# ADuCM410 register map
Vendor: Analog Devices; Series: ADuCM410; File version: 1p0
CPU: CM33 r0p1, little endian, MPU, FPU, 3 interrupt priority bits
Registers are 32-bit, read-write, reset 0x0 unless marked. A register's access mark holds for its fields unless they carry their own. Offsets are from the block's base; [hi:lo] are bit positions; lines under a group give offsets from that group; {n}, {i} and the like mark numbered series; 'fields as' and 'values as' point back to an identical list.

## PLA
Base 0x40006000
{0x0+4i} ELMxcon[{i}] (i=0..31) group — ELMx Configuration Registers
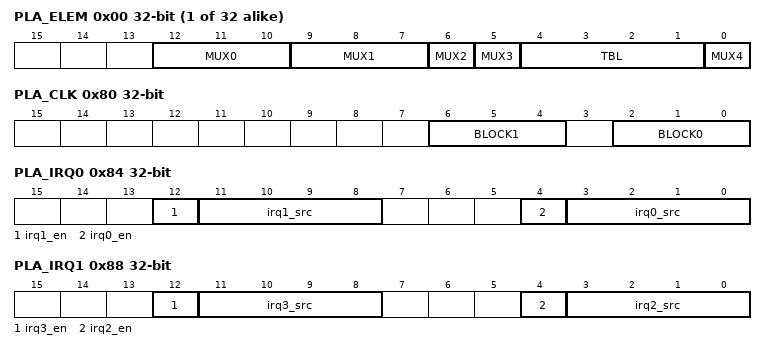
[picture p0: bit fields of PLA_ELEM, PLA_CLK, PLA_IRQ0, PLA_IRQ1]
  0x00 PLA_ELEM — ELEMx Configuration Register
    [12:10] MUX0 — Mux for Even Element Feedback(in Respective Block)
      0=ELEM0 (Feedback from Element 0 (all Except Element 0) / Input from Other Block (Element 0 Only)); 1=ELEM2 (Feedback from Element 2); 2=ELEM4 (Feedback from Element 4); 3=ELEM6 (Feedback from Element 6); 4=ELEM8 (Feedback from Element 8); 5=ELEM10 (Feedback from Element 10); 6=ELEM12 (Feedback from Element 12); 7=ELEM14 (Feedback from Element 14)
    [9:7] MUX1 — Mux for Odd Element Feedback (In Respective Block)
      0=ELEM1 (Feedback from Element 1); 1=ELEM3 (Feedback from Element 3); 2=ELEM5 (Feedback from Element 5); 3=ELEM7 (Feedback from Element 7); 4=ELEM9 (Feedback from Element 9); 5=ELEM11 (Feedback from Element 11); 6=ELEM13 (Feedback from Element 13); 7=ELEM15 (Feedback from Element 15)
    [6] MUX2 — Mux Between PLA_DINx Register/Block0 Output or Even Feedback
      0=MMR (PLA_DINx Input); 1=EVEN (Even Feedback Mux)
    [5] MUX3 — Mux Between GPIO Bus Input or Odd Feedback Input
      0=ODD (Odd Feedback Mux); 1=GPIO (GPIO Input)
    [4:1] TBL — Configures Output
      0=LOW (0.); 1=FUN_NOR (NOR.); 2=BANDNOTA; 3=NOTA; 4=AANDNOTB; 5=NOTB; 6=EXOR; 7=FUN_NAND (NAND.); 8=FUN_AND (AND.); 9=EXNOR; 10=B; 11=BORNOTA; 12=A; 13=AORNOTB; 14=FUN_OR (OR); 15=HIGH (1.)
    [0] MUX4 — Select or Bypass Flip-flop Output
      0=FF (FF Output); 1=BYPASS (Bypass Output)
0x80 PLA_CLK — PLA Clock Select
  [6:4] BLOCK1 — Clock Select for Block 1
    0=PLACLK0 (GPIO Clock 0); 1=PLACLK1 (GPIO Clock 1); 2=PLACLK2 (GPIO Clock 2); 3=PCLK0; 4=MOSC (MOSC (16 MHz)); 5=T0 (Timer 0); 6=T2 (Timer 2); 7=KOSC (KOSC (32 KHz))
  [2:0] BLOCK0 — Clock Select for Block 0
    values as BLOCK1
0x84 PLA_IRQ0 — Interrupt Register for Block 0
  [12] irq1_en — IRQ1 Enable
    0=DIS (Disable IRQ1 Interrupt); 1=EN (Enable IRQ1 Interrupt)
  [11:8] irq1_src range 0x00000000..0x0000000F — IRQ1 Source Select
  [4] irq0_en — IRQ0 Enable
    0=DIS (Disable IRQ0 Interrupt); 1=EN (Enable IRQ0 Interrupt)
  [3:0] irq0_src range 0x00000000..0x0000000F — IRQ0 Source Select
0x88 PLA_IRQ1 — Interrupt Register for Block1
  [12] irq3_en — IRQ3 Enable
    0=DIS (Disable IRQ3 Interrupt); 1=EN (Enable IRQ3 Interrupt)
  [11:8] irq3_src range 0x00000000..0x0000000F — IRQ3 Source Select
  [4] irq2_en — IRQ2 Enable
    0=DIS (Disable IRQ2 Interrupt); 1=EN (Enable IRQ2 Interrupt)
  [3:0] irq2_src range 0x00000000..0x0000000F — IRQ2 Source Select
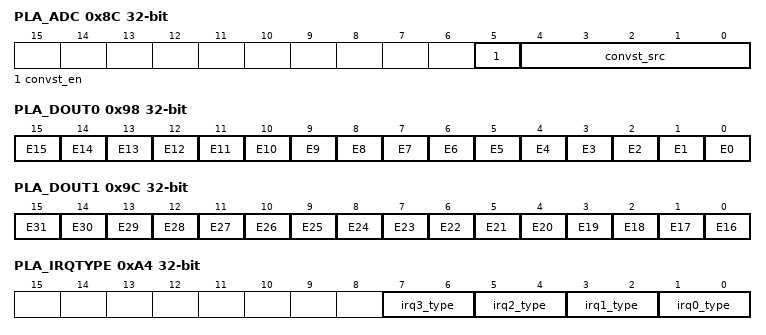
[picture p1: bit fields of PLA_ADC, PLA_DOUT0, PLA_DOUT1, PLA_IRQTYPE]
0x8C PLA_ADC — ADC Configuration Register
  [5] convst_en — Bit to Enable ADC Start Convert from PLA
    0=DISABLE; 1=ENABLE
  [4:0] convst_src range 0x00000000..0x0000001F — Element for ADC Start Convert Source
0x90 PLA_DIN0 — AMBA Bus Data Input for Block 0
  [15:0] DIN range 0x00000000..0x0000FFFF — Input Bit to Element 15 to Element 0.
0x98 PLA_DOUT0 — AMBA Bus Data Output for Block 0
  [n] E{n} ro (n=0..15) — Output Bit from Element {n}
0x9C PLA_DOUT1 — AMBA Bus Data Output for Block1
  [n-16] E{n} ro (n=16..31) — Output Bit from Element {n}
0xA0 PLA_LCK — Write Lock Register.
  [0] LOCKED — Set to Disable Writing to Registers
    0=DIS (Writing to Registers Allowed); 1=EN (Writing to Registers Disabled)
0xA4 PLA_IRQTYPE — PLA Interrupt Request and DMA Request Type
  [7:6] irq3_type — IRQ3 and DMA Request 3 Type
    0=High Level Trigger Interrupt and High Level Trigger DMA Request; 1=Rising Edge Trigger Interrupt and High Level Trigger DMA Request; 2=Low Level Trigger Interrupt and Low Level Trigger DMA Request; 3=Falling Edge Trigger Interrupt and Low Level Trigger DMA Request
  [5:4] irq2_type — IRQ2 and DMA Request 2 Type
    values as irq3_type
  [3:2] irq1_type — IRQ1 and DMA Request 1Type
    values as irq3_type
  [1:0] irq0_type — IRQ0 and DMA Request 0 Type
    0=High Level Trigger Interrupt and High Level Trigger DMA Request; 1=Rising Edge Trigger Interrupt and Rising Edge Trigger DMA Request; 2=Low Level Trigger Interrupt and Low Level Trigger DMA Request; 3=Falling Edge Trigger Interrupt and Falling Edge Trigger DMA Request
